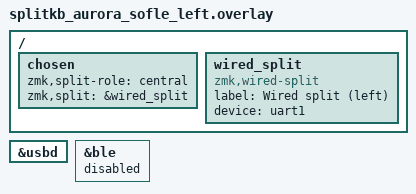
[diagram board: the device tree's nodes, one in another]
/ {
    chosen {
        zmk,split-role = "central";
        zmk,split = &wired_split;
    };

    wired_split: wired_split {
        compatible = "zmk,wired-split";
        label = "Wired split (left)";
        device = <&uart1>;   /* TRRS TX/RX połączenie */
    };
};

&usbd {
    status = "okay";
};

&ble {
    status = "disabled";
};
